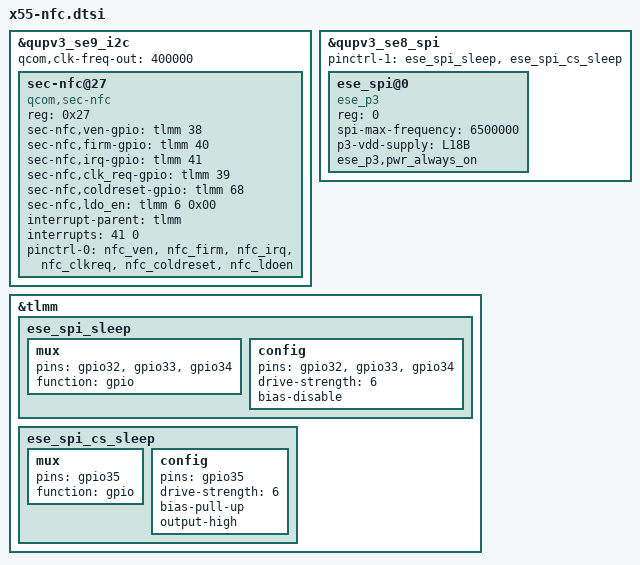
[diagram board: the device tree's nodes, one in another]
&qupv3_se9_i2c {
	status = "ok";
	qcom,clk-freq-out = <400000>;
	#address-cells = <1>;
	#size-cells = <0>;
	sec-nfc@27 {
		compatible = "qcom,sec-nfc";
		reg = <0x27>;
		sec-nfc,ven-gpio = <&tlmm 38 0x00>;  /*gpio_38   NFCPD*/
		sec-nfc,firm-gpio = <&tlmm 40 0x00>;  /*gpio_40   NFC_WAKE_UP*/
		sec-nfc,irq-gpio = <&tlmm 41 0x00>;  /*gpio_41     NFC_IRQ*/
		sec-nfc,clk_req-gpio = <&tlmm 39 0x00>;  /*gpio_39    NFC_CLK_REQ*/
		sec-nfc,coldreset-gpio= <&tlmm 68 0x00>; /*gpio_68    NFC_COLDREST*/
		sec-nfc,ldo_en = <&tlmm 6 0x00>; /*gpio_6    NFC_LDO_EN*/
		interrupt-parent = <&tlmm>;
		interrupts = <41 0>;
		interrupt-names = "nfc_irq";
		pinctrl-names = "default";
		pinctrl-0 = <&nfc_ven &nfc_firm &nfc_irq &nfc_clkreq &nfc_coldreset &nfc_ldoen>;
	};
};

/* eSE */
&qupv3_se8_spi {
	status = "ok";
	pinctrl-1 = <&ese_spi_sleep &ese_spi_cs_sleep>;
	ese_spi@0 {
		compatible = "ese_p3";
		reg = <0>;
		spi-max-frequency = <6500000>;
		p3-vdd-supply = <&L18B>;
		ese_p3,pwr_always_on;
	};
};

&tlmm {
	ese_spi_sleep: ese_spi_sleep {
		mux {
			pins = "gpio32", "gpio33",
				"gpio34";
			function = "gpio";
		};
		config {
			pins = "gpio32", "gpio33",
				"gpio34";
			drive-strength = <6>;
			bias-disable;
		};
	};
	ese_spi_cs_sleep: ese_spi_cs_sleep {
		mux {
			pins = "gpio35";
			function = "gpio";
		};
		config {
			pins = "gpio35";
			drive-strength = <6>;
			bias-pull-up;
			output-high;
		};
	};
};
